# ISD9100_v3 register map
File version: 1.0
Registers are 32-bit, read-write, reset 0x0 unless marked. A register's access mark holds for its fields unless they carry their own. Offsets are from the block's base; [hi:lo] are bit positions.

## DPWM — DPWM Register Map
Base 0x40070000
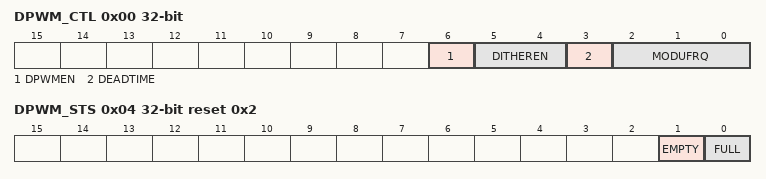
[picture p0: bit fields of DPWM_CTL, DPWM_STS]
0x00 DPWM_CTL — DPWM Control Register
  [6] DPWMEN — DPWM Enable
    0=Disable DPWM, SPK pins are tri-state, CIC filter is reset, FIFO pointers are reset (FIFO data is not reset); 1=Enable DPWM, SPK pins are enabled and driven, data is taken from FIFO
  [5:4] DITHEREN — DPWM Signal Dither Control. To prevent structured noise on PWM output due to DC offsets in the input signal it is possible to add random dither to the PWM signal. These bits control the dither:
    0=No dither; 1=+/- 1 bit dither; 3=+/- 2 bit dither
  [3] DEADTIME — DPWM Driver Deadtime Control. Enabling this bit will insert an additional clock cycle deadtime into the switching of PMOS and NMOS driver transistors.
  [2:0] MODUFRQ — DPWM Modulation Frequency. This parameter controls the carrier modulation frequency of the PWM signal as a proportion of DPWM_CLK. MODUFRQ : DPWM_CLK Division : Frequency for DPWM_CLK aaa 98.304MHZ. 0 : 228 : 431158. 1 : 156 : 630154. 2 : 76 : 1293474. 3 : 52 : 1890462. 4 : 780 : 126031. 5 : 524 : 187603. 6 : 396 : 248242. 7 : 268 : 366806
0x04 DPWM_STS ro reset 0x2 — DPWM FIFO Status Register
  [1] EMPTY — FIFO Empty
    0=FIFO is not empty; 1=FIFO is empty
  [0] FULL — FIFO Full
    0=FIFO is not full; 1=FIFO is full
0x08 DPWM_DMACTL — DPWM PDMA Control Register
  [0] DMAEN — Enable DPWM DMA Interface
    0=Disable PDMA. No requests will be made to PDMA controller; 1=Enable PDMA. Block will request data from PDMA controller whenever FIFO is not empty
0x0C DPWM_DATA wo — DPWM FIFO Input
  [15:0] INDATA — DPWM FIFO Audio Data Input. A write to this register pushes data onto the DPWM FIFO and increments the write pointer. This is the address that PDMA writes audio data to.
0x10 DPWM_ZOHDIV reset 0x30 — DPWM Zero Order Hold Division Register
  [7:0] ZOHDIV — DPWM Zero Order Hold, Down-Sampling Divisor. The input sample rate of the DPWM is set by HCLK frequency and the divisor set in this register by the following formula: Fs aaa HCLK/ZOHDIV/64. Valid range is 1 to 255. Default is 48, which gives a sample rate of 16kHz for a 49.152MHz (default) HCLK.

## ACMP — ACMP Register Map
Base 0x400D0000
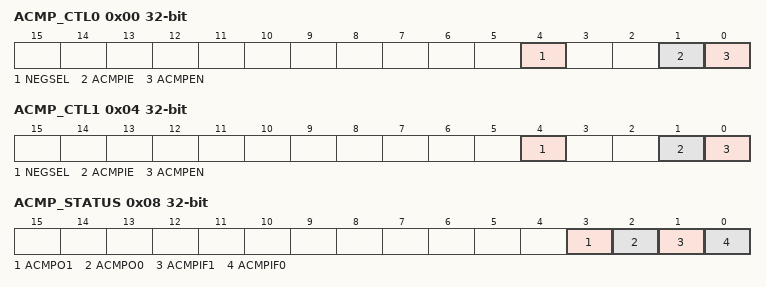
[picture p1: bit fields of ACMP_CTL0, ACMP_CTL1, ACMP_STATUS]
0x00 ACMP_CTL0 — Analog Comparator 0 Control Register
  [4] NEGSEL — Comparator0 Negative Input Select
    0=VBG, Bandgap reference voltage aaa 1.2V; 1=VMID reference voltage aaa VCCA/2
  [1] ACMPIE — CMP0 Interrupt Enable
    0=Disable CMP0 interrupt function; 1=Enable CMP0 interrupt function
  [0] ACMPEN — Comparator Enable
    0=Disable; 1=Enable
0x04 ACMP_CTL1 — Analog Comparator 1 Control Register
  [4] NEGSEL — Comparator1 Negative Input Select
    0=GPIOB[7]; 1=VBG, Bandgap reference voltage aaa 1.2V
  [1] ACMPIE — CMP1 Interrupt Enable
    0=Disable CMP1interrupt function; 1=Enable CMP1 interrupt function
  [0] ACMPEN — Comparator Enable
    0=Disable; 1=Enable
0x08 ACMP_STATUS (reset mask 0xFFFFFF00) — Comparator Status Register
  [3] ACMPO1 — Comparator1 Output. Synchronized to the APB clock to allow reading by software. Cleared when the comparator is disabled (CMP1EN aaa 0).
  [2] ACMPO0 — Comparator0 Output. Synchronized to the APB clock to allow reading by software. Cleared when the comparator is disabled (CMP0EN aaa 0).
  [1] ACMPIF1 — Compare 1 Flag. This bit is set by hardware whenever the comparator output changes state. This bit will cause a hardware interrupt if enabled. This bit is cleared by writing 1 to itself.
  [0] ACMPIF0 — Compare 0 Flag. This bit is set by hardware whenever the comparator output changes state. This bit will cause a hardware interrupt if enabled. This bit is cleared by writing 1 to itself.
0x0C ACMP_POSSEL — Comparator Select Register
  [2:0] POSSEL — Comparator0 GPIO Selection. GPIOB[POSSEL] is the active analog GPIO input selected to Comparator 0 positive input.
